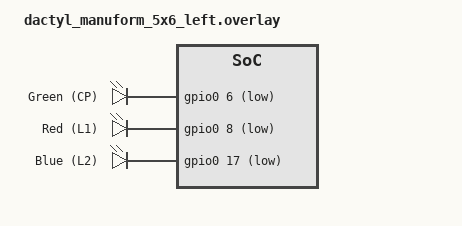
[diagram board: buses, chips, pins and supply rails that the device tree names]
#include "dactyl_manuform_5x6.dtsi" // Notice that the main dtsi files are included in the overlay.
#include <dt-bindings/zmk/hid_indicators.h>

&kscan0 {
    col-gpios
        = <&gpio0 20 GPIO_ACTIVE_HIGH>
        , <&gpio0 22 GPIO_ACTIVE_HIGH>
        , <&gpio0 24 GPIO_ACTIVE_HIGH>
        , <&gpio1 0 GPIO_ACTIVE_HIGH>
        , <&gpio0 11 GPIO_ACTIVE_HIGH>
        , <&gpio1 4 GPIO_ACTIVE_HIGH>
        , <&gpio1 6 GPIO_ACTIVE_HIGH>
        ;
};

/ {
	// Green and blue are driven by src/dactyl_leds.c; red is Caps Lock below.
	// These merge into the nice!nano's own leds node, which already uses the
	// blue_led label for its onboard LED, hence the status_ prefix.
	aliases {
		dactyl-led-green = &status_green_led;
		dactyl-led-blue = &status_blue_led;
	};

	leds {
		compatible = "gpio-leds";

		status_green_led: led_green {
			gpios = <&gpio0 6 GPIO_ACTIVE_LOW>;
			label = "Green (CP)";
		};

		status_red_led: led_red {
			gpios = <&gpio0 8 GPIO_ACTIVE_LOW>;
			label = "Red (L1)";
		};

		status_blue_led: led_blue {
			gpios = <&gpio0 17 GPIO_ACTIVE_LOW>;
			label = "Blue (L2)";
		};
	};

	indicators {
		compatible = "zmk,indicator-leds";

		caps_lock_indicator: caps_lock {
			indicator = <HID_INDICATOR_CAPS_LOCK>;
			leds = <&status_red_led>;
		};
	};
};
